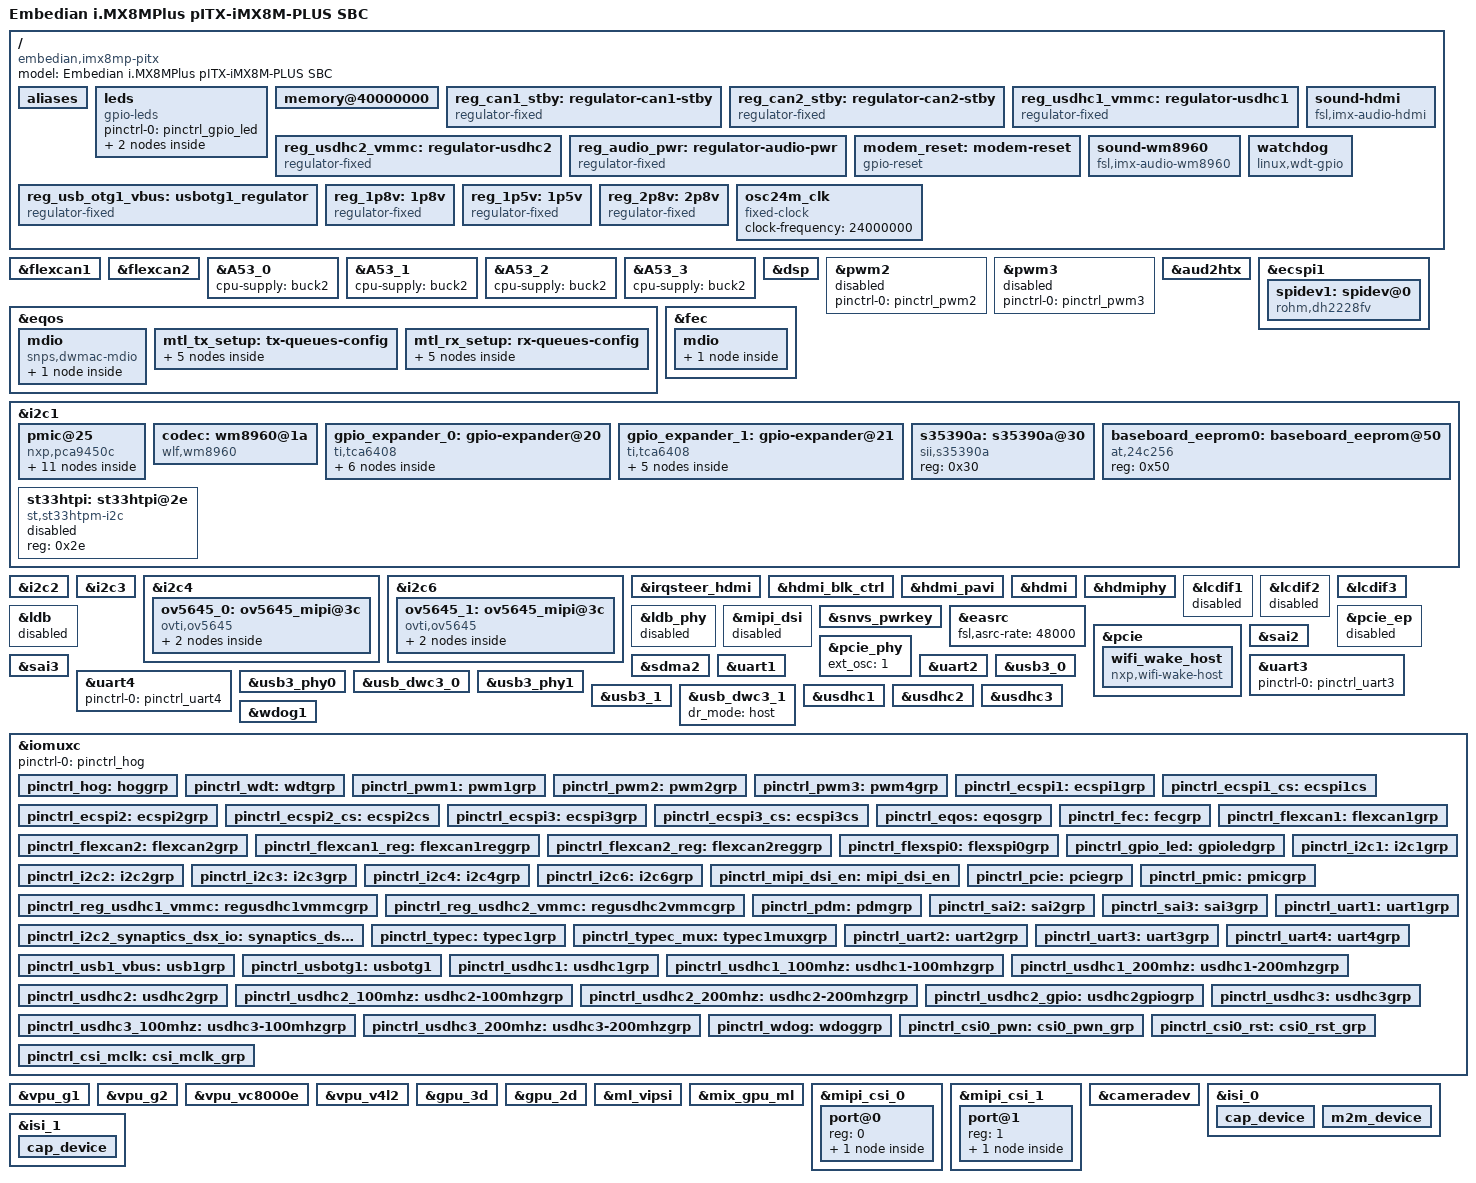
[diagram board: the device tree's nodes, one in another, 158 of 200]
// SPDX-License-Identifier: (GPL-2.0+ OR MIT)
/*
 * Copyright 2019 NXP
 * Copyright 2023 Embedian, Inc.
 */

/dts-v1/;

#include <dt-bindings/usb/pd.h>
#include "../freescale/imx8mp.dtsi"

/ {
	model = "Embedian i.MX8MPlus pITX-iMX8M-PLUS SBC";
	compatible = "embedian,imx8mp-pitx", "fsl,imx8mp";

	aliases {
		rtc0 = &s35390a;
		rtc1 = &snvs_rtc;
	};

	leds {
		compatible = "gpio-leds";
		pinctrl-names = "default";
		pinctrl-0 = <&pinctrl_gpio_led>;

		/* fault may in the event of a kernel panic, but if you want to set it manually,
		   echo 149 > /sys/class/leds/fault/brightness */

		led1 {
			label = "led1";
			gpios = <&gpio5 21 GPIO_ACTIVE_HIGH>;
			default-state = "off";
			linux,default-trigger = "heartbeat";
		};

		watchdog_enable {
			label = "watchdog_enable";
			gpios = <&gpio4 27 GPIO_ACTIVE_HIGH>;
			default-state = "on";
		};
	};

	memory@40000000 {
		device_type = "memory";
		reg = <0x0 0x40000000 0 0xc0000000>,
		      <0x1 0x00000000 0 0xc0000000>;
	};

	reg_can1_stby: regulator-can1-stby {
		compatible = "regulator-fixed";
		regulator-name = "can1-stby";
		regulator-min-microvolt = <3300000>;
		regulator-max-microvolt = <3300000>;
	};

	reg_can2_stby: regulator-can2-stby {
		compatible = "regulator-fixed";
		regulator-name = "can2-stby";
		regulator-min-microvolt = <3300000>;
		regulator-max-microvolt = <3300000>;
	};

	reg_usdhc1_vmmc: regulator-usdhc1 {
		compatible = "regulator-fixed";
		pinctrl-names = "default";
		pinctrl-0 = <&pinctrl_reg_usdhc1_vmmc>;
		regulator-name = "VSD1_3V3";
		regulator-min-microvolt = <3300000>;
		regulator-max-microvolt = <3300000>;
		gpio = <&gpio2 10 GPIO_ACTIVE_HIGH>;
		enable-active-high;
	};

	reg_usdhc2_vmmc: regulator-usdhc2 {
		compatible = "regulator-fixed";
		pinctrl-names = "default";
		pinctrl-0 = <&pinctrl_reg_usdhc2_vmmc>;
		regulator-name = "VSD2_3V3";
		regulator-min-microvolt = <3300000>;
		regulator-max-microvolt = <3300000>;
		gpio = <&gpio2 19 GPIO_ACTIVE_HIGH>;
		enable-active-high;
	};

	reg_audio_pwr: regulator-audio-pwr {
		compatible = "regulator-fixed";
		regulator-name = "aud-pwr";
		regulator-min-microvolt = <3300000>;
		regulator-max-microvolt = <3300000>;
		regulator-always-on;
	};

	modem_reset: modem-reset {
		compatible = "gpio-reset";
		reset-gpios = <&gpio_expander_1 3 GPIO_ACTIVE_LOW>;
		reset-delay-us = <2000>;
		reset-post-delay-ms = <40>;
	};

	sound-hdmi {
		compatible = "fsl,imx-audio-hdmi";
		model = "audio-hdmi";
		audio-cpu = <&aud2htx>;
		hdmi-out;
		constraint-rate = <44100>,
				<88200>,
				<176400>,
				<32000>,
				<48000>,
				<96000>,
				<192000>;
		status = "okay";
	};

	sound-wm8960 {
		compatible = "fsl,imx-audio-wm8960";
		model = "wm8960-audio";
		audio-cpu = <&sai3>;
		audio-codec = <&codec>;
		audio-asrc = <&easrc>;
		hp-det-gpio = <&gpio4 28 0>;
		audio-routing =
			"Headphone Jack", "HP_L",
			"Headphone Jack", "HP_R",
			"Ext Spk", "SPK_LP",
			"Ext Spk", "SPK_LN",
			"Ext Spk", "SPK_RP",
			"Ext Spk", "SPK_RN",
			"LINPUT1", "Mic Jack",
			"LINPUT3", "Mic Jack",
			"Mic Jack", "MICB";
	};

	watchdog: watchdog {
		compatible = "linux,wdt-gpio";
		pinctrl-names = "default";
		pinctrl-0 = <&pinctrl_wdt>;
		gpios = <&gpio4 2 GPIO_ACTIVE_LOW>;
		hw_algo = "toggle";
		hw_margin_ms = <80>;
		always-running;
	};

	reg_usb_otg1_vbus: usbotg1_regulator {
		compatible = "regulator-fixed";
		regulator-name = "usb_otg1_vbus";
		regulator-min-microvolt = <3300000>;
		regulator-max-microvolt = <3300000>;
		gpio = <&gpio1 12 GPIO_ACTIVE_HIGH>;
		enable-active-high;
		regulator-always-on;
	};

	reg_1p8v: 1p8v {
		compatible = "regulator-fixed";
		regulator-name = "1P8V";
		regulator-min-microvolt = <1800000>;
		regulator-max-microvolt = <1800000>;
		regulator-always-on;
	};

	reg_1p5v: 1p5v {
		compatible = "regulator-fixed";
		regulator-name = "1P5V";
		regulator-min-microvolt = <1500000>;
		regulator-max-microvolt = <1500000>;
		regulator-always-on;
	};

	reg_2p8v: 2p8v {
		compatible = "regulator-fixed";
		regulator-name = "2P8V";
		regulator-min-microvolt = <2800000>;
		regulator-max-microvolt = <2800000>;
		regulator-always-on;
	};

	osc24m_clk: osc24m_clk {
		compatible = "fixed-clock";
		#clock-cells = <0>;
		clock-frequency = <24000000>;
	};
};

&flexcan1 {
	pinctrl-names = "default";
	pinctrl-0 = <&pinctrl_flexcan1>;
	xceiver-supply = <&reg_can1_stby>;
	status = "okay";
};

&flexcan2 {
	pinctrl-names = "default";
	pinctrl-0 = <&pinctrl_flexcan2>;
	xceiver-supply = <&reg_can2_stby>;
	status = "okay";
};

&A53_0 {
	cpu-supply = <&buck2>;
};

&A53_1 {
	cpu-supply = <&buck2>;
};

&A53_2 {
	cpu-supply = <&buck2>;
};

&A53_3 {
	cpu-supply = <&buck2>;
};

&dsp {
	status = "okay";
};

&pwm2 {
	pinctrl-names = "default";
	pinctrl-0 = <&pinctrl_pwm2>;
	status = "disabled";
};

&pwm3 {
	pinctrl-names = "default";
	pinctrl-0 = <&pinctrl_pwm3>;
	status = "disabled";
};

&aud2htx {
	status = "okay";
};

/* SPI (on pIO) */
&ecspi1 {
	#address-cells = <1>;
	#size-cells = <0>;
	fsl,spi-num-chipselects = <1>;
	pinctrl-names = "default";
	pinctrl-0 = <&pinctrl_ecspi1 &pinctrl_ecspi1_cs>;
	cs-gpios = <&gpio5 9 GPIO_ACTIVE_LOW>;
	status = "okay";

	spidev1: spidev@0 {
		reg = <0>;
		compatible = "rohm,dh2228fv";
		spi-max-frequency = <24000000>;
	};
};

&eqos {
	pinctrl-names = "default";
	pinctrl-0 = <&pinctrl_eqos>;
	phy-mode = "rgmii-id";
	phy-handle = <&ethphy1>;
	snps,force_thresh_dma_mode;
	snps,mtl-tx-config = <&mtl_tx_setup>;
	snps,mtl-rx-config = <&mtl_rx_setup>;
	status = "okay";

	mdio {
		compatible = "snps,dwmac-mdio";
		#address-cells = <1>;
		#size-cells = <0>;

		ethphy1: ethernet-phy@1 {
			compatible = "ethernet-phy-ieee802.3-c22";
			reg = <1>;
			eee-broken-1000t;
			realtek,clkout-disable;
		};
	};

	mtl_tx_setup: tx-queues-config {
		snps,tx-queues-to-use = <5>;
		snps,tx-sched-sp;
		queue0 {
			snps,dcb-algorithm;
			snps,priority = <0x1>;
		};
		queue1 {
			snps,dcb-algorithm;
			snps,priority = <0x2>;
		};
		queue2 {
			snps,dcb-algorithm;
			snps,priority = <0x4>;
		};
		queue3 {
			snps,dcb-algorithm;
			snps,priority = <0x8>;
		};
		queue4 {
			snps,dcb-algorithm;
			snps,priority = <0xf0>;
		};
	};
	mtl_rx_setup: rx-queues-config {
		snps,rx-queues-to-use = <5>;
		snps,rx-sched-sp;
		queue0 {
			snps,dcb-algorithm;
			snps,priority = <0x1>;
			snps,map-to-dma-channel = <0>;
		};
		queue1 {
			snps,dcb-algorithm;
			snps,priority = <0x2>;
			snps,map-to-dma-channel = <1>;
		};
		queue2 {
			snps,dcb-algorithm;
			snps,priority = <0x4>;
			snps,map-to-dma-channel = <2>;
		};
		queue3 {
			snps,dcb-algorithm;
			snps,priority = <0x8>;
			snps,map-to-dma-channel = <3>;
		};
		queue4 {
			snps,dcb-algorithm;
			snps,priority = <0xf0>;
			snps,map-to-dma-channel = <4>;
		};
	};
};

&fec {
	pinctrl-names = "default";
	pinctrl-0 = <&pinctrl_fec>;
	phy-mode = "rgmii-id";
	phy-handle = <&ethphy0>;
	fsl,magic-packet;
	status = "okay";

	mdio {
		#address-cells = <1>;
		#size-cells = <0>;

		ethphy0: ethernet-phy@1 {
			compatible = "ethernet-phy-ieee802.3-c22";
			reg = <1>;
			eee-broken-1000t;
			realtek,aldps-enable;
			realtek,clkout-disable;
		};
	};
};

/* I2C1 */
&i2c1 {
	clock-frequency = <400000>;
	pinctrl-names = "default";
	pinctrl-0 = <&pinctrl_i2c1>;
	status = "okay";

	pmic@25 {
		compatible = "nxp,pca9450c";
		reg = <0x25>;
		pinctrl-names = "default";
		pinctrl-0 = <&pinctrl_pmic>;
		interrupt-parent = <&gpio1>;
		interrupts = <3 IRQ_TYPE_LEVEL_LOW>;

		regulators {
			buck1: BUCK1 {
				regulator-name = "BUCK1";
				regulator-min-microvolt = <600000>;
				regulator-max-microvolt = <2187500>;
				regulator-boot-on;
				regulator-always-on;
				regulator-ramp-delay = <3125>;
			};

			buck2: BUCK2 {
				regulator-name = "BUCK2";
				regulator-min-microvolt = <600000>;
				regulator-max-microvolt = <2187500>;
				regulator-boot-on;
				regulator-always-on;
				regulator-ramp-delay = <3125>;
				nxp,dvs-run-voltage = <950000>;
				nxp,dvs-standby-voltage = <850000>;
			};

			buck4: BUCK4{
				regulator-name = "BUCK4";
				regulator-min-microvolt = <600000>;
				regulator-max-microvolt = <3400000>;
				regulator-boot-on;
				regulator-always-on;
			};

			buck5: BUCK5{
				regulator-name = "BUCK5";
				regulator-min-microvolt = <600000>;
				regulator-max-microvolt = <3400000>;
				regulator-boot-on;
				regulator-always-on;
			};

			buck6: BUCK6 {
				regulator-name = "BUCK6";
				regulator-min-microvolt = <600000>;
				regulator-max-microvolt = <3400000>;
				regulator-boot-on;
				regulator-always-on;
			};

			ldo1: LDO1 {
				regulator-name = "LDO1";
				regulator-min-microvolt = <1600000>;
				regulator-max-microvolt = <3300000>;
				regulator-boot-on;
				regulator-always-on;
			};

			ldo2: LDO2 {
				regulator-name = "LDO2";
				regulator-min-microvolt = <800000>;
				regulator-max-microvolt = <1150000>;
				regulator-boot-on;
				regulator-always-on;
			};

			ldo3: LDO3 {
				regulator-name = "LDO3";
				regulator-min-microvolt = <800000>;
				regulator-max-microvolt = <3300000>;
				regulator-boot-on;
				regulator-always-on;
			};

			ldo4: LDO4 {
				regulator-name = "LDO4";
				regulator-min-microvolt = <800000>;
				regulator-max-microvolt = <3300000>;
				regulator-boot-on;
				regulator-always-on;
			};

			ldo5: LDO5 {
				regulator-name = "LDO5";
				regulator-min-microvolt = <1800000>;
				regulator-max-microvolt = <3300000>;
				regulator-boot-on;
				regulator-always-on;
			};
		};
	};

	codec: wm8960@1a {
		compatible = "wlf,wm8960";
		reg = <0x1a>;
		clocks = <&audio_blk_ctrl IMX8MP_CLK_AUDIO_BLK_CTRL_SAI3_MCLK1>;
		clock-names = "mclk";
		wlf,shared-lrclk;
		wlf,hp-cfg = <3 2 3>;
		wlf,gpio-cfg = <1 3>;
		SPKVDD1-supply = <&reg_audio_pwr>;
	};

	/*
	 * TCA6408 GPIO expander
	 *  0-WLAN_PWR_EN
	 *  1-M2_W_DISABLE1#
	 *  2-M2_W_DISABLE2#
	 *  3-M2_RESET#
	 *  4-PCIE_A_CKREQ#
	 *  5-PCIE_A_WAKE#
	 *  6-UART_WAKE#
	 *  7-
	*/
	gpio_expander_0: gpio-expander@20 {
		compatible = "ti,tca6408";
		reg = <0x20>;
		gpio-controller;
		vcc-supply = <&reg_1p8v>;
		#gpio-cells = <2>;
		interrupt-controller;
		#interrupt-cells = <2>;
		interrupt-parent = <&gpio4>;
		interrupts = <22 IRQ_TYPE_LEVEL_LOW>;

		wlan_pwr_en_hog {
			gpio-hog;
			gpios = <0 GPIO_ACTIVE_HIGH>;
			output-high;
			line-name = "wlan_pwr_en";
		};
		m2_w_disable1_hog {
			gpio-hog;
			gpios = <1 GPIO_ACTIVE_LOW>;
			output-low;
			line-name = "m2_w_disable1";
		};
		m2_w_disable2_hog {
			gpio-hog;
			gpios = <2 GPIO_ACTIVE_LOW>;
			output-low;
			line-name = "m2_w_disable2";
		};
		pcie_a_ckreq_hog {
			gpio-hog;
			gpios = <4 GPIO_ACTIVE_LOW>;
			input;
			line-name = "pcie_a_ckreq";
		};
		pcie_a_wake_hog {
			gpio-hog;
			gpios = <5 GPIO_ACTIVE_LOW>;
			input;
			line-name = "pcie_a_wake";
		};
		uart_wake_hog {
			gpio-hog;
			gpios = <6 GPIO_ACTIVE_LOW>;
			input;
			line-name = "uart_wake";
		};
	};

	/*
	 * TCA6408 GPIO expander
	 *  0-WWLAN_PWR_EN
	 *  1-WWAN_DISABLE1#
	 *  2-WWAN_DISABLE2#
	 *  3-WWAN_PERST#
	 *  4-NC
	 *  5-WWAN_WAKE#
	 *  6-NC
	 *  7-UIM_CD
	*/
	gpio_expander_1: gpio-expander@21 {
		compatible = "ti,tca6408";
		reg = <0x21>;
		gpio-controller;
		vcc-supply = <&reg_1p8v>;
		#gpio-cells = <2>;
		interrupt-controller;
		#interrupt-cells = <2>;
		interrupt-parent = <&gpio5>;
		interrupts = <0 IRQ_TYPE_LEVEL_LOW>;

		wwan_pwr_en_hog {
			gpio-hog;
			gpios = <0 GPIO_ACTIVE_HIGH>;
			output-high;
			line-name = "wwan_pwr_en";
		};
		wwan_w_disable1_hog {
			gpio-hog;
			gpios = <1 GPIO_ACTIVE_LOW>;
			output-low;
			line-name = "wwan_w_disable1";
		};
		wwan_w_disable2_hog {
			gpio-hog;
			gpios = <2 GPIO_ACTIVE_LOW>;
			output-low;
			line-name = "wwan_w_disable2";
		};
		wwan_wake_hog {
			gpio-hog;
			gpios = <5 GPIO_ACTIVE_LOW>;
			input;
			line-name = "wwan_wake";
		};
		uim_cd_hog {
			gpio-hog;
			gpios = <7 GPIO_ACTIVE_HIGH>;
			input;
			line-name = "uim_cd";
		};
	};

	s35390a: s35390a@30 {
		compatible = "sii,s35390a";
		reg = <0x30>;
	};

	baseboard_eeprom0: baseboard_eeprom@50 {
		compatible = "at,24c256";
		reg = <0x50>;
	};

	/* TPM */
	st33htpi: st33htpi@2e{
		compatible = "st,st33htpm-i2c";
		reg = <0x2e>;
		status = "disabled";
	};
};

/* I2C2 (LVDS) */
&i2c2 {
	clock-frequency = <100000>;
	pinctrl-names = "default";
	pinctrl-0 = <&pinctrl_i2c2>;
	status = "okay";
};

/* I2C3 (on pIO) */
&i2c3 {
	clock-frequency = <400000>;
	pinctrl-names = "default";
	pinctrl-0 = <&pinctrl_i2c3>;
	status = "okay";
};

/* I2C4 (on CAM2 and pIO) */
&i2c4 {
	clock-frequency = <400000>;
	pinctrl-names = "default";
	pinctrl-0 = <&pinctrl_i2c4>;
	status = "okay";

	ov5645_0: ov5645_mipi@3c {
		compatible = "ovti,ov5645";
		reg = <0x3c>;
		clocks = <&osc24m_clk>;
		clock-frequency = <24000000>;
		clock-names = "xclk";
		vdddo-supply = <&reg_1p8v>;
		vdda-supply = <&reg_2p8v>;
		vddd-supply = <&reg_1p5v>;
		csi_id = <1>;
		enable-gpios = <&gpio3 8 GPIO_ACTIVE_HIGH>;
		reset-gpios = <&gpio3 9 GPIO_ACTIVE_LOW>;
		mipi_csi;
                status = "okay";

                port {
                        ov5645_mipi_1_ep: endpoint {
                                remote-endpoint = <&mipi_csi1_ep>;
                                data-lanes = <1 2>;
                                clock-lanes = <0>;
                        };
                };
        };
};

/* I2C6 (on CAM1)*/
&i2c6 {
	clock-frequency = <400000>;
	pinctrl-names = "default";
	pinctrl-0 = <&pinctrl_i2c6>;
	status = "okay";

	ov5645_1: ov5645_mipi@3c {
		compatible = "ovti,ov5645";
		reg = <0x3c>;
		clocks = <&osc24m_clk>;
		clock-names = "xclk";
		clock-frequency = <24000000>;
		vdddo-supply = <&reg_1p8v>;
		vdda-supply = <&reg_2p8v>;
		vddd-supply = <&reg_1p5v>;
		csi_id = <0>;
		enable-gpios = <&gpio3 6 GPIO_ACTIVE_HIGH>;
		reset-gpios = <&gpio3 7 GPIO_ACTIVE_LOW>;
		mipi_csi;
                status = "okay";

                port {
                        ov5645_mipi_0_ep: endpoint {
                                remote-endpoint = <&mipi_csi0_ep>;
				data-lanes = <1 2>;
                                clock-lanes = <0>;
                        };
                };
        };
};

&irqsteer_hdmi {
	status = "okay";
};

&hdmi_blk_ctrl {
	status = "okay";
};

&hdmi_pavi {
	status = "okay";
};

&hdmi {
	status = "okay";
};

&hdmiphy {
	status = "okay";
};

/* MIPI-DSI */
&lcdif1 {
	status = "disabled";
};

/* LVDS */
&lcdif2 {
	status = "disabled";
};

/* HDMI */
&lcdif3 {
	status = "okay";

	thres-low  = <1 2>;		/* (FIFO * 1 / 2) */
	thres-high = <3 4>;		/* (FIFO * 3 / 4) */
};

&ldb {
	status = "disabled";
};

&ldb_phy {
	status = "disabled";
};

&mipi_dsi {
	status = "disabled";
};

&snvs_pwrkey {
	status = "okay";
};

&easrc {
	fsl,asrc-rate  = <48000>;
	status = "okay";
};

&pcie{
	pinctrl-names = "default";
	pinctrl-0 = <&pinctrl_pcie>;
	reset-gpio = <&gpio_expander_0 3 GPIO_ACTIVE_LOW>;
	ext_osc = <1>;
	clocks = <&clk IMX8MP_CLK_HSIO_ROOT>,
		 <&clk IMX8MP_CLK_PCIE_AUX>,
		 <&clk IMX8MP_CLK_HSIO_AXI>,
		 <&clk IMX8MP_CLK_PCIE_ROOT>;
	clock-names = "pcie", "pcie_aux", "pcie_phy", "pcie_bus";
	assigned-clocks = <&clk IMX8MP_CLK_HSIO_AXI>,
			  <&clk IMX8MP_CLK_PCIE_AUX>;
	assigned-clock-rates = <500000000>, <10000000>;
	assigned-clock-parents = <&clk IMX8MP_SYS_PLL2_500M>,
				 <&clk IMX8MP_SYS_PLL2_50M>;
	l1ss-disabled;
	status = "okay";

	wifi_wake_host {
		compatible = "nxp,wifi-wake-host";
		interrupt-parent = <&gpio2>;
		interrupts = <7 IRQ_TYPE_LEVEL_LOW>;
		interrupt-names = "host-wake";
	};
};

&pcie_ep{
	pinctrl-names = "default";
	pinctrl-0 = <&pinctrl_pcie>;
	ext_osc = <1>;
	clocks = <&clk IMX8MP_CLK_HSIO_ROOT>,
		 <&clk IMX8MP_CLK_PCIE_AUX>,
		 <&clk IMX8MP_CLK_HSIO_AXI>,
		 <&clk IMX8MP_CLK_PCIE_ROOT>;
	clock-names = "pcie", "pcie_aux", "pcie_phy", "pcie_bus";
	assigned-clocks = <&clk IMX8MP_CLK_HSIO_AXI>,
			  <&clk IMX8MP_CLK_PCIE_AUX>;
	assigned-clock-rates = <500000000>, <10000000>;
	assigned-clock-parents = <&clk IMX8MP_SYS_PLL2_500M>,
				 <&clk IMX8MP_SYS_PLL2_50M>;
	status = "disabled";
};

&pcie_phy{
	ext_osc = <1>;
	status = "okay";
};

/* M.2 */
&sai2 {
	#sound-dai-cells = <0>;
	pinctrl-names = "default";
	pinctrl-0 = <&pinctrl_sai2>;
	assigned-clocks = <&clk IMX8MP_CLK_SAI2>;
	assigned-clock-parents = <&clk IMX8MP_AUDIO_PLL1_OUT>;
	assigned-clock-rates = <24576000>;
	status = "okay";
};

&sai3 {
	pinctrl-names = "default";
	pinctrl-0 = <&pinctrl_sai3>;
	assigned-clocks = <&clk IMX8MP_CLK_SAI3>;
	assigned-clock-parents = <&clk IMX8MP_AUDIO_PLL1_OUT>;
	assigned-clock-rates = <24576000>;
	clocks = <&audio_blk_ctrl IMX8MP_CLK_AUDIO_BLK_CTRL_SAI3_IPG>, <&clk IMX8MP_CLK_DUMMY>,
		 <&audio_blk_ctrl IMX8MP_CLK_AUDIO_BLK_CTRL_SAI3_MCLK1>, <&clk IMX8MP_CLK_DUMMY>,
		 <&clk IMX8MP_CLK_DUMMY>;
	clock-names = "bus", "mclk0", "mclk1", "mclk2", "mclk3";
	fsl,sai-mclk-direction-output;
	status = "okay";
};

&sdma2 {
	status = "okay";
};

&uart1 { 
	/* M.2 */
	pinctrl-names = "default";
	pinctrl-0 = <&pinctrl_uart1>;
	assigned-clocks = <&clk IMX8MP_CLK_UART1>;
	assigned-clock-parents = <&clk IMX8MP_SYS_PLL1_80M>;
	fsl,uart-has-rtscts;
	status = "okay";
};

&uart2 {
	/* pIO */
	pinctrl-names = "default";
	pinctrl-0 = <&pinctrl_uart2>;
	assigned-clocks = <&clk IMX8MP_CLK_UART2>;
	assigned-clock-parents = <&clk IMX8MP_SYS_PLL1_80M>;
	fsl,uart-has-rtscts;
	status = "okay";
};

&uart3 {
	/* pIO */
	pinctrl-names = "default";
	pinctrl-0 = <&pinctrl_uart3>;
	status = "okay";
};

&uart4 {
	/* console */
	pinctrl-names = "default";
	pinctrl-0 = <&pinctrl_uart4>;
	status = "okay";
};

&usb3_phy0 {
	fsl,phy-tx-vref-tune = <0xe>;
	fsl,phy-tx-preemp-amp-tune = <3>;
	fsl,phy-tx-vboost-level = <5>;
	fsl,phy-comp-dis-tune = <7>;
	fsl,pcs-tx-deemph-3p5db = <0x21>;
	fsl,phy-pcs-tx-swing-full = <0x7f>;
	status = "okay";
};

&usb3_0 {
	pinctrl-names = "default";
	pinctrl-0 = <&pinctrl_usbotg1>;
	vbus-supply = <&reg_usb_otg1_vbus>;
	status = "okay";
};

&usb_dwc3_0 {
	dr_mode = "otg";
	hnp-disable;
	srp-disable;
	adp-disable;
	usb-role-switch;
	role-switch-default-mode = "host";
	snps,dis-u1-entry-quirk;
	snps,dis-u2-entry-quirk;
	status = "okay";
};

&usb3_phy1 {
	fsl,phy-tx-preemp-amp-tune = <3>;
	fsl,phy-tx-vref-tune = <0xb>;
	status = "okay";
};

&usb3_1 {
	status = "okay";
};

&usb_dwc3_1 {
	dr_mode = "host";
	status = "okay";
};

/* M.2 */
&usdhc1 {
	assigned-clocks = <&clk IMX8MP_CLK_USDHC1>;
	assigned-clock-rates = <400000000>;
	pinctrl-names = "default", "state_100mhz", "state_200mhz";
	pinctrl-0 = <&pinctrl_usdhc1>;
	pinctrl-1 = <&pinctrl_usdhc1_100mhz>;
	pinctrl-2 = <&pinctrl_usdhc1_200mhz>;
	vmmc-supply = <&reg_usdhc1_vmmc>;
	bus-width = <4>;
	pm-ignore-notify;
	keep-power-in-suspend;
	non-removable;
	cap-power-off-card;
	status = "okay";
};

/* SD Card */
&usdhc2 {
	assigned-clocks = <&clk IMX8MP_CLK_USDHC2>;
	assigned-clock-rates = <400000000>;
	pinctrl-names = "default", "state_100mhz", "state_200mhz";
	pinctrl-0 = <&pinctrl_usdhc2>, <&pinctrl_usdhc2_gpio>;
	pinctrl-1 = <&pinctrl_usdhc2_100mhz>, <&pinctrl_usdhc2_gpio>;
	pinctrl-2 = <&pinctrl_usdhc2_200mhz>, <&pinctrl_usdhc2_gpio>;
	cd-gpios = <&gpio2 12 GPIO_ACTIVE_LOW>;
	vmmc-supply = <&reg_usdhc2_vmmc>;
	bus-width = <4>;
	status = "okay";
};

/* eMMC */
&usdhc3 {
	assigned-clocks = <&clk IMX8MP_CLK_USDHC3>;
	assigned-clock-rates = <400000000>;
	pinctrl-names = "default", "state_100mhz", "state_200mhz";
	pinctrl-0 = <&pinctrl_usdhc3>;
	pinctrl-1 = <&pinctrl_usdhc3_100mhz>;
	pinctrl-2 = <&pinctrl_usdhc3_200mhz>;
	bus-width = <8>;
	non-removable;
	status = "okay";
};

&wdog1 {
	pinctrl-names = "default";
	pinctrl-0 = <&pinctrl_wdog>;
	fsl,ext-reset-output;
	status = "okay";
};

&iomuxc {
	pinctrl-names = "default";
	pinctrl-0 = <&pinctrl_hog>;

	pinctrl_hog: hoggrp {
		fsl,pins = <
			MX8MP_IOMUXC_HDMI_DDC_SCL__HDMIMIX_HDMI_SCL	0x400001c2
			MX8MP_IOMUXC_HDMI_DDC_SDA__HDMIMIX_HDMI_SDA	0x400001c2
			MX8MP_IOMUXC_HDMI_HPD__HDMIMIX_HDMI_HPD		0x40000010
			MX8MP_IOMUXC_HDMI_CEC__HDMIMIX_HDMI_CEC		0x40000010
			MX8MP_IOMUXC_SAI1_TXD6__GPIO4_IO18	0x19	/* LCD0_BKLT_EN */
			MX8MP_IOMUXC_SAI1_MCLK__GPIO4_IO20	0x19	/* LCD1_BKLT_EN */
			MX8MP_IOMUXC_SAI1_RXC__GPIO4_IO01	0x19	/* LCD0_VDD_EN */
			MX8MP_IOMUXC_SD2_WP__GPIO2_IO20		0x41	/* M.2_IRQ# */
			MX8MP_IOMUXC_SAI1_TXD7__GPIO4_IO19	0x141	/* TPM_IRQ# */
			MX8MP_IOMUXC_ECSPI2_MOSI__GPIO5_IO11	0x41	/* TPM_PP */
			MX8MP_IOMUXC_ECSPI2_SCLK__GPIO5_IO10	0x41	/* TPM_LP */
			MX8MP_IOMUXC_SAI2_RXC__GPIO4_IO22	0x41	/* TCA6408 IO Expander INT# (M.2) */
			MX8MP_IOMUXC_SAI3_TXC__GPIO5_IO00	0x41	/* TCA6408 IO Expander INT# (MPCIe) */
			MX8MP_IOMUXC_GPIO1_IO15__GPIO1_IO15	0x41	/* TS_INT# */
			MX8MP_IOMUXC_NAND_DQS__GPIO3_IO14	0x19	/* USB2_HUB_EN */
			MX8MP_IOMUXC_NAND_DATA00__GPIO3_IO06	0x19	/* CAM1_PWR# */
			MX8MP_IOMUXC_NAND_DATA01__GPIO3_IO07	0x19	/* CAM1_RST# */
			MX8MP_IOMUXC_SAI3_RXC__GPIO4_IO29	0x41	/* CAM1_VSYNC */
			MX8MP_IOMUXC_NAND_DATA02__GPIO3_IO08	0x19	/* CAM2_PWR# */
			MX8MP_IOMUXC_NAND_DATA03__GPIO3_IO09	0x19	/* CAM2_RST# */
			MX8MP_IOMUXC_SPDIF_EXT_CLK__GPIO5_IO05	0x19	/* EIO_PWR_EN */
			MX8MP_IOMUXC_SAI1_RXFS__GPIO4_IO00	0x41	/* CAM2_VSYNC */
		>;
	};

	pinctrl_wdt: wdtgrp {
		fsl,pins = <
			MX8MP_IOMUXC_SAI2_MCLK__GPIO4_IO27	0x19	/* WDT_EN */
			MX8MP_IOMUXC_SAI1_RXD0__GPIO4_IO02	0x19	/* WDT_T_ME_OUT# */
		>;
	};

	pinctrl_pwm1: pwm1grp {
		fsl,pins = <
			MX8MP_IOMUXC_GPIO1_IO01__PWM1_OUT	0x116
		>;
	};

	pinctrl_pwm2: pwm2grp {
		fsl,pins = <
			MX8MP_IOMUXC_SAI5_RXD0__PWM2_OUT	0x116
		>;
	};

	pinctrl_pwm3: pwm4grp {
		fsl,pins = <
			MX8MP_IOMUXC_SPDIF_TX__PWM3_OUT		0x116
		>;
	};

	pinctrl_ecspi1: ecspi1grp {
		fsl,pins = <
			MX8MP_IOMUXC_ECSPI1_SCLK__ECSPI1_SCLK	0x82
			MX8MP_IOMUXC_ECSPI1_MOSI__ECSPI1_MOSI	0x82
			MX8MP_IOMUXC_ECSPI1_MISO__ECSPI1_MISO	0x82
		>;
	};

	pinctrl_ecspi1_cs: ecspi1cs {
		fsl,pins = <
			MX8MP_IOMUXC_ECSPI1_SS0__GPIO5_IO09	0x40000
		>;
	};

	pinctrl_ecspi2: ecspi2grp {
		fsl,pins = <
			MX8MP_IOMUXC_ECSPI2_SCLK__ECSPI2_SCLK	0x82
			MX8MP_IOMUXC_ECSPI2_MOSI__ECSPI2_MOSI	0x82
			MX8MP_IOMUXC_ECSPI2_MISO__ECSPI2_MISO	0x82
		>;
	};

	pinctrl_ecspi2_cs: ecspi2cs {
		fsl,pins = <
			MX8MP_IOMUXC_ECSPI2_SS0__GPIO5_IO13	0x40000
		>;
	};

	pinctrl_ecspi3: ecspi3grp {
		fsl,pins = <
			MX8MP_IOMUXC_UART1_RXD__ECSPI3_SCLK	0x82
			MX8MP_IOMUXC_UART1_TXD__ECSPI3_MOSI	0x82
			MX8MP_IOMUXC_UART2_RXD__ECSPI3_MISO	0x82
		>;
	};

	pinctrl_ecspi3_cs: ecspi3cs {
		fsl,pins = <
			MX8MP_IOMUXC_UART2_TXD__GPIO5_IO25	0x40000
			MX8MP_IOMUXC_UART3_RXD__GPIO5_IO26	0x40000
		>;
	};

	pinctrl_eqos: eqosgrp {
		fsl,pins = <
			MX8MP_IOMUXC_ENET_MDC__ENET_QOS_MDC				0x2
			MX8MP_IOMUXC_ENET_MDIO__ENET_QOS_MDIO				0x2
			MX8MP_IOMUXC_ENET_RD0__ENET_QOS_RGMII_RD0			0x90
			MX8MP_IOMUXC_ENET_RD1__ENET_QOS_RGMII_RD1			0x90
			MX8MP_IOMUXC_ENET_RD2__ENET_QOS_RGMII_RD2			0x90
			MX8MP_IOMUXC_ENET_RD3__ENET_QOS_RGMII_RD3			0x90
			MX8MP_IOMUXC_ENET_RXC__CCM_ENET_QOS_CLOCK_GENERATE_RX_CLK	0x90
			MX8MP_IOMUXC_ENET_RX_CTL__ENET_QOS_RGMII_RX_CTL			0x90
			MX8MP_IOMUXC_ENET_TD0__ENET_QOS_RGMII_TD0			0x16
			MX8MP_IOMUXC_ENET_TD1__ENET_QOS_RGMII_TD1			0x16
			MX8MP_IOMUXC_ENET_TD2__ENET_QOS_RGMII_TD2			0x16
			MX8MP_IOMUXC_ENET_TD3__ENET_QOS_RGMII_TD3			0x16
			MX8MP_IOMUXC_ENET_TX_CTL__ENET_QOS_RGMII_TX_CTL			0x16
			MX8MP_IOMUXC_ENET_TXC__CCM_ENET_QOS_CLOCK_GENERATE_TX_CLK	0x16
			MX8MP_IOMUXC_SAI2_RXFS__GPIO4_IO21				0x42
		>;
	};

	pinctrl_fec: fecgrp {
		fsl,pins = <
			MX8MP_IOMUXC_SAI1_RXD2__ENET1_MDC		0x2
			MX8MP_IOMUXC_SAI1_RXD3__ENET1_MDIO		0x2
			MX8MP_IOMUXC_SAI1_RXD4__ENET1_RGMII_RD0		0x90
			MX8MP_IOMUXC_SAI1_RXD5__ENET1_RGMII_RD1		0x90
			MX8MP_IOMUXC_SAI1_RXD6__ENET1_RGMII_RD2		0x90
			MX8MP_IOMUXC_SAI1_RXD7__ENET1_RGMII_RD3		0x90
			MX8MP_IOMUXC_SAI1_TXC__ENET1_RGMII_RXC		0x90
			MX8MP_IOMUXC_SAI1_TXFS__ENET1_RGMII_RX_CTL	0x90
			MX8MP_IOMUXC_SAI1_TXD0__ENET1_RGMII_TD0		0x16
			MX8MP_IOMUXC_SAI1_TXD1__ENET1_RGMII_TD1		0x16
			MX8MP_IOMUXC_SAI1_TXD2__ENET1_RGMII_TD2		0x16
			MX8MP_IOMUXC_SAI1_TXD3__ENET1_RGMII_TD3		0x16
			MX8MP_IOMUXC_SAI1_TXD4__ENET1_RGMII_TX_CTL	0x16
			MX8MP_IOMUXC_SAI1_TXD5__ENET1_RGMII_TXC		0x16
			MX8MP_IOMUXC_SAI1_RXD1__GPIO4_IO03		0x42
		>;
	};

	pinctrl_flexcan1: flexcan1grp {
		fsl,pins = <
			MX8MP_IOMUXC_SAI5_RXD2__CAN1_RX		0x154
			MX8MP_IOMUXC_SAI5_RXD1__CAN1_TX		0x154
		>;
	};

	pinctrl_flexcan2: flexcan2grp {
		fsl,pins = <
			MX8MP_IOMUXC_SAI5_MCLK__CAN2_RX		0x154
			MX8MP_IOMUXC_SAI5_RXD3__CAN2_TX		0x154
		>;
	};

	pinctrl_flexcan1_reg: flexcan1reggrp {
		fsl,pins = <
			MX8MP_IOMUXC_SPDIF_EXT_CLK__GPIO5_IO05	0x154	/* CAN1_STBY */
		>;
	};

	pinctrl_flexcan2_reg: flexcan2reggrp {
		fsl,pins = <
			MX8MP_IOMUXC_SAI2_MCLK__GPIO4_IO27	0x154	/* CAN2_STBY */
		>;
	};

	pinctrl_flexspi0: flexspi0grp {
		fsl,pins = <
			MX8MP_IOMUXC_NAND_ALE__FLEXSPI_A_SCLK           0x1c2
			MX8MP_IOMUXC_NAND_CE0_B__FLEXSPI_A_SS0_B        0x82
			MX8MP_IOMUXC_NAND_DATA00__FLEXSPI_A_DATA00      0x82
			MX8MP_IOMUXC_NAND_DATA01__FLEXSPI_A_DATA01      0x82
			MX8MP_IOMUXC_NAND_DATA02__FLEXSPI_A_DATA02      0x82
			MX8MP_IOMUXC_NAND_DATA03__FLEXSPI_A_DATA03      0x82
		>;
	};

	pinctrl_gpio_led: gpioledgrp {
		fsl,pins = <
			MX8MP_IOMUXC_I2C4_SDA__GPIO5_IO21	0x19
		>;
	};

	pinctrl_i2c1: i2c1grp {
		fsl,pins = <
			MX8MP_IOMUXC_I2C1_SCL__I2C1_SCL		0x400001c2
			MX8MP_IOMUXC_I2C1_SDA__I2C1_SDA		0x400001c2
		>;
	};

	pinctrl_i2c2: i2c2grp {
		fsl,pins = <
			MX8MP_IOMUXC_I2C2_SCL__I2C2_SCL		0x400001c2
			MX8MP_IOMUXC_I2C2_SDA__I2C2_SDA		0x400001c2
		>;
	};

	pinctrl_i2c3: i2c3grp {
		fsl,pins = <
			MX8MP_IOMUXC_I2C3_SCL__I2C3_SCL		0x400001c2
			MX8MP_IOMUXC_I2C3_SDA__I2C3_SDA		0x400001c2
		>;
	};

	pinctrl_i2c4: i2c4grp {
		fsl,pins = <
			MX8MP_IOMUXC_ECSPI2_MISO__I2C4_SCL	0x400001c3
			MX8MP_IOMUXC_ECSPI2_SS0__I2C4_SDA	0x400001c3
		>;
	};

	pinctrl_i2c6: i2c6grp {
		fsl,pins = <
			MX8MP_IOMUXC_SAI5_RXFS__I2C6_SCL	0x400001c3
			MX8MP_IOMUXC_SAI5_RXC__I2C6_SDA		0x400001c3
		>;
	};

	pinctrl_mipi_dsi_en: mipi_dsi_en {
		fsl,pins = <
			MX8MP_IOMUXC_GPIO1_IO08__GPIO1_IO08	0x16
		>;
	};

	pinctrl_pcie: pciegrp {
		fsl,pins = <
			MX8MP_IOMUXC_I2C4_SCL__PCIE_CLKREQ_B		0x60 /* open drain, pull up */
		>;
	};

	pinctrl_pmic: pmicgrp {
		fsl,pins = <
			MX8MP_IOMUXC_GPIO1_IO03__GPIO1_IO03	0x000001c0
		>;
	};

	pinctrl_reg_usdhc1_vmmc: regusdhc1vmmcgrp {
		fsl,pins = <
			MX8MP_IOMUXC_SD1_RESET_B__GPIO2_IO10    0x41
		>;
	};

	pinctrl_reg_usdhc2_vmmc: regusdhc2vmmcgrp {
		fsl,pins = <
			MX8MP_IOMUXC_SD2_RESET_B__GPIO2_IO19	0x40
		>;
	};

	pinctrl_pdm: pdmgrp {
		fsl,pins = <
			MX8MP_IOMUXC_SAI5_RXC__AUDIOMIX_PDM_CLK		0xd6
			MX8MP_IOMUXC_SAI5_RXD0__AUDIOMIX_PDM_BIT_STREAM00	0xd6
			MX8MP_IOMUXC_SAI5_RXD1__AUDIOMIX_PDM_BIT_STREAM01	0xd6
			MX8MP_IOMUXC_SAI5_RXD2__AUDIOMIX_PDM_BIT_STREAM02	0xd6
			MX8MP_IOMUXC_SAI5_RXD3__AUDIOMIX_PDM_BIT_STREAM03	0xd6
		>;
	};

	pinctrl_sai2: sai2grp {
		fsl,pins = <
			MX8MP_IOMUXC_SAI2_TXC__AUDIOMIX_SAI2_TX_BCLK	0xd6
			MX8MP_IOMUXC_SAI2_TXFS__AUDIOMIX_SAI2_TX_SYNC	0xd6
			MX8MP_IOMUXC_SAI2_TXD0__AUDIOMIX_SAI2_TX_DATA00	0xd6
			MX8MP_IOMUXC_SAI2_RXD0__AUDIOMIX_SAI2_RX_DATA00	0xd6
		>;
	};

	pinctrl_sai3: sai3grp {
		fsl,pins = <
			MX8MP_IOMUXC_SAI3_TXFS__AUDIOMIX_SAI3_TX_SYNC		0xd6
			MX8MP_IOMUXC_NAND_ALE__AUDIOMIX_SAI3_TX_BCLK		0xd6
			MX8MP_IOMUXC_SAI3_RXD__AUDIOMIX_SAI3_RX_DATA00		0xd6
			MX8MP_IOMUXC_NAND_CE0_B__AUDIOMIX_SAI3_TX_DATA00	0xd6
			MX8MP_IOMUXC_SAI3_MCLK__AUDIOMIX_SAI3_MCLK		0xd6
			MX8MP_IOMUXC_SAI3_RXFS__GPIO4_IO28			0x41
		>;
	};

	pinctrl_i2c2_synaptics_dsx_io: synaptics_dsx_iogrp {
		fsl,pins = <
			MX8MP_IOMUXC_GPIO1_IO09__GPIO1_IO09		0x16
		>;
	};

	pinctrl_uart1: uart1grp {
		fsl,pins = <
			MX8MP_IOMUXC_UART1_RXD__UART1_DCE_RX	0x140
			MX8MP_IOMUXC_UART1_TXD__UART1_DCE_TX	0x140
			MX8MP_IOMUXC_UART3_RXD__UART1_DCE_CTS	0x140
			MX8MP_IOMUXC_UART3_TXD__UART1_DCE_RTS	0x140
		>;
	};

	pinctrl_typec: typec1grp {
		fsl,pins = <
			MX8MP_IOMUXC_SAI1_TXD7__GPIO4_IO19	0x1c4
		>;
	};

	pinctrl_typec_mux: typec1muxgrp {
		fsl,pins = <
			MX8MP_IOMUXC_SAI1_MCLK__GPIO4_IO20	0x16
		>;
	};

	pinctrl_uart2: uart2grp {
		fsl,pins = <
			MX8MP_IOMUXC_UART2_RXD__UART2_DCE_RX	0x140
			MX8MP_IOMUXC_UART2_TXD__UART2_DCE_TX	0x140
			MX8MP_IOMUXC_SD1_DATA4__UART2_DCE_RTS	0x140
			MX8MP_IOMUXC_SD1_DATA5__UART2_DCE_CTS	0x140
		>;
	};

	pinctrl_uart3: uart3grp {
		fsl,pins = <
			MX8MP_IOMUXC_SD1_DATA7__UART3_DCE_RX	0x49
			MX8MP_IOMUXC_SD1_DATA6__UART3_DCE_TX	0x49
		>;
	};

	pinctrl_uart4: uart4grp {
		fsl,pins = <
			MX8MP_IOMUXC_UART4_RXD__UART4_DCE_RX	0x140
			MX8MP_IOMUXC_UART4_TXD__UART4_DCE_TX	0x140
		>;
	};

	pinctrl_usb1_vbus: usb1grp {
		fsl,pins = <
			MX8MP_IOMUXC_GPIO1_IO14__USB2_PWR	0x10
		>;
	};

	pinctrl_usbotg1: usbotg1 {
		fsl,pins = <
			MX8MP_IOMUXC_GPIO1_IO10__USB1_ID	0x41	/* USB1_ID */
			MX8MP_IOMUXC_GPIO1_IO12__GPIO1_IO12	0x19	/* USB1_EN */
			MX8MP_IOMUXC_GPIO1_IO13__GPIO1_IO13	0x41	/* USB1_OC# */
		>;
	};

	pinctrl_usdhc1: usdhc1grp {
		fsl,pins = <
			MX8MP_IOMUXC_SD1_CLK__USDHC1_CLK	0x190
			MX8MP_IOMUXC_SD1_CMD__USDHC1_CMD	0x1d0
			MX8MP_IOMUXC_SD1_DATA0__USDHC1_DATA0	0x1d0
			MX8MP_IOMUXC_SD1_DATA1__USDHC1_DATA1	0x1d0
			MX8MP_IOMUXC_SD1_DATA2__USDHC1_DATA2	0x1d0
			MX8MP_IOMUXC_SD1_DATA3__USDHC1_DATA3	0x1d0
			MX8MP_IOMUXC_SD1_STROBE__USDHC1_STROBE	0x190
		>;
	};

	pinctrl_usdhc1_100mhz: usdhc1-100mhzgrp {
		fsl,pins = <
			MX8MP_IOMUXC_SD1_CLK__USDHC1_CLK	0x194
			MX8MP_IOMUXC_SD1_CMD__USDHC1_CMD	0x1d4
			MX8MP_IOMUXC_SD1_DATA0__USDHC1_DATA0	0x1d4
			MX8MP_IOMUXC_SD1_DATA1__USDHC1_DATA1	0x1d4
			MX8MP_IOMUXC_SD1_DATA2__USDHC1_DATA2	0x1d4
			MX8MP_IOMUXC_SD1_DATA3__USDHC1_DATA3	0x1d4
			MX8MP_IOMUXC_SD1_STROBE__USDHC1_STROBE	0x194
		>;
	};

	pinctrl_usdhc1_200mhz: usdhc1-200mhzgrp {
		fsl,pins = <
			MX8MP_IOMUXC_SD1_CLK__USDHC1_CLK	0x196
			MX8MP_IOMUXC_SD1_CMD__USDHC1_CMD	0x1d6
			MX8MP_IOMUXC_SD1_DATA0__USDHC1_DATA0	0x1d6
			MX8MP_IOMUXC_SD1_DATA1__USDHC1_DATA1	0x1d6
			MX8MP_IOMUXC_SD1_DATA2__USDHC1_DATA2	0x1d6
			MX8MP_IOMUXC_SD1_DATA3__USDHC1_DATA3	0x1d6
			MX8MP_IOMUXC_SD1_STROBE__USDHC1_STROBE	0x196
		>;
	};

	pinctrl_usdhc2: usdhc2grp {
		fsl,pins = <
			MX8MP_IOMUXC_SD2_CLK__USDHC2_CLK	0x190
			MX8MP_IOMUXC_SD2_CMD__USDHC2_CMD	0x1d0
			MX8MP_IOMUXC_SD2_DATA0__USDHC2_DATA0	0x1d0
			MX8MP_IOMUXC_SD2_DATA1__USDHC2_DATA1	0x1d0
			MX8MP_IOMUXC_SD2_DATA2__USDHC2_DATA2	0x1d0
			MX8MP_IOMUXC_SD2_DATA3__USDHC2_DATA3	0x1d0
			MX8MP_IOMUXC_GPIO1_IO04__USDHC2_VSELECT	0xc0
		>;
	};

	pinctrl_usdhc2_100mhz: usdhc2-100mhzgrp {
		fsl,pins = <
			MX8MP_IOMUXC_SD2_CLK__USDHC2_CLK	0x194
			MX8MP_IOMUXC_SD2_CMD__USDHC2_CMD	0x1d4
			MX8MP_IOMUXC_SD2_DATA0__USDHC2_DATA0	0x1d4
			MX8MP_IOMUXC_SD2_DATA1__USDHC2_DATA1	0x1d4
			MX8MP_IOMUXC_SD2_DATA2__USDHC2_DATA2	0x1d4
			MX8MP_IOMUXC_SD2_DATA3__USDHC2_DATA3	0x1d4
			MX8MP_IOMUXC_GPIO1_IO04__USDHC2_VSELECT 0xc0
		>;
	};

	pinctrl_usdhc2_200mhz: usdhc2-200mhzgrp {
		fsl,pins = <
			MX8MP_IOMUXC_SD2_CLK__USDHC2_CLK	0x196
			MX8MP_IOMUXC_SD2_CMD__USDHC2_CMD	0x1d6
			MX8MP_IOMUXC_SD2_DATA0__USDHC2_DATA0	0x1d6
			MX8MP_IOMUXC_SD2_DATA1__USDHC2_DATA1	0x1d6
			MX8MP_IOMUXC_SD2_DATA2__USDHC2_DATA2	0x1d6
			MX8MP_IOMUXC_SD2_DATA3__USDHC2_DATA3	0x1d6
			MX8MP_IOMUXC_GPIO1_IO04__USDHC2_VSELECT 0xc0
		>;
	};

	pinctrl_usdhc2_gpio: usdhc2gpiogrp {
		fsl,pins = <
			MX8MP_IOMUXC_SD2_CD_B__GPIO2_IO12	0x1c4
		>;
	};

	pinctrl_usdhc3: usdhc3grp {
		fsl,pins = <
			MX8MP_IOMUXC_NAND_WE_B__USDHC3_CLK	0x190
			MX8MP_IOMUXC_NAND_WP_B__USDHC3_CMD	0x1d0
			MX8MP_IOMUXC_NAND_DATA04__USDHC3_DATA0	0x1d0
			MX8MP_IOMUXC_NAND_DATA05__USDHC3_DATA1	0x1d0
			MX8MP_IOMUXC_NAND_DATA06__USDHC3_DATA2	0x1d0
			MX8MP_IOMUXC_NAND_DATA07__USDHC3_DATA3	0x1d0
			MX8MP_IOMUXC_NAND_RE_B__USDHC3_DATA4	0x1d0
			MX8MP_IOMUXC_NAND_CE2_B__USDHC3_DATA5	0x1d0
			MX8MP_IOMUXC_NAND_CE3_B__USDHC3_DATA6	0x1d0
			MX8MP_IOMUXC_NAND_CLE__USDHC3_DATA7	0x1d0
			MX8MP_IOMUXC_NAND_CE1_B__USDHC3_STROBE	0x190
		>;
	};

	pinctrl_usdhc3_100mhz: usdhc3-100mhzgrp {
		fsl,pins = <
			MX8MP_IOMUXC_NAND_WE_B__USDHC3_CLK	0x194
			MX8MP_IOMUXC_NAND_WP_B__USDHC3_CMD	0x1d4
			MX8MP_IOMUXC_NAND_DATA04__USDHC3_DATA0	0x1d4
			MX8MP_IOMUXC_NAND_DATA05__USDHC3_DATA1	0x1d4
			MX8MP_IOMUXC_NAND_DATA06__USDHC3_DATA2	0x1d4
			MX8MP_IOMUXC_NAND_DATA07__USDHC3_DATA3	0x1d4
			MX8MP_IOMUXC_NAND_RE_B__USDHC3_DATA4	0x1d4
			MX8MP_IOMUXC_NAND_CE2_B__USDHC3_DATA5	0x1d4
			MX8MP_IOMUXC_NAND_CE3_B__USDHC3_DATA6	0x1d4
			MX8MP_IOMUXC_NAND_CLE__USDHC3_DATA7	0x1d4
			MX8MP_IOMUXC_NAND_CE1_B__USDHC3_STROBE	0x194
		>;
	};

	pinctrl_usdhc3_200mhz: usdhc3-200mhzgrp {
		fsl,pins = <
			MX8MP_IOMUXC_NAND_WE_B__USDHC3_CLK	0x196
			MX8MP_IOMUXC_NAND_WP_B__USDHC3_CMD	0x1d6
			MX8MP_IOMUXC_NAND_DATA04__USDHC3_DATA0	0x1d6
			MX8MP_IOMUXC_NAND_DATA05__USDHC3_DATA1	0x1d6
			MX8MP_IOMUXC_NAND_DATA06__USDHC3_DATA2	0x1d6
			MX8MP_IOMUXC_NAND_DATA07__USDHC3_DATA3	0x1d6
			MX8MP_IOMUXC_NAND_RE_B__USDHC3_DATA4	0x1d6
			MX8MP_IOMUXC_NAND_CE2_B__USDHC3_DATA5	0x1d6
			MX8MP_IOMUXC_NAND_CE3_B__USDHC3_DATA6	0x1d6
			MX8MP_IOMUXC_NAND_CLE__USDHC3_DATA7	0x1d6
			MX8MP_IOMUXC_NAND_CE1_B__USDHC3_STROBE	0x196
		>;
	};

	pinctrl_wdog: wdoggrp {
		fsl,pins = <
			MX8MP_IOMUXC_GPIO1_IO02__WDOG1_WDOG_B	0x166
		>;
	};

	pinctrl_csi0_pwn: csi0_pwn_grp {
		fsl,pins = <
			MX8MP_IOMUXC_NAND_DATA00__GPIO3_IO06	0x10
		>;
	};

	pinctrl_csi0_rst: csi0_rst_grp {
		fsl,pins = <
			MX8MP_IOMUXC_NAND_DATA01__GPIO3_IO07	0x10
		>;
	};

	pinctrl_csi_mclk: csi_mclk_grp {
		fsl,pins = <
			MX8MP_IOMUXC_GPIO1_IO14__CCM_CLKO1	0x50
		>;
	};
};

&vpu_g1 {
	status = "okay";
};

&vpu_g2 {
	status = "okay";
};

&vpu_vc8000e {
	status = "okay";
};

&vpu_v4l2 {
	status = "okay";
};

&gpu_3d {
	status = "okay";
};

&gpu_2d {
	status = "okay";
};

&ml_vipsi {
	status = "okay";
};

&mix_gpu_ml {
	status = "okay";
};

&mipi_csi_0 {
	#address-cells = <1>;
	#size-cells = <0>;
	status = "okay";

	port@0 {
		reg = <0>;
		mipi_csi0_ep: endpoint {
			remote-endpoint = <&ov5645_mipi_0_ep>;
			data-lanes = <2>;
			csis-hs-settle = <13>;
			csis-clk-settle = <2>;
			csis-wclk;
		};
	};
};

&mipi_csi_1 {
	#address-cells = <1>;
	#size-cells = <0>;
	status = "okay";

	/* Camera 1  MIPI CSI-2 (CSIS1) */
	port@1 {
		reg = <1>;
		mipi_csi1_ep: endpoint {
			remote-endpoint = <&ov5645_mipi_1_ep>;
			data-lanes = <2>;
			csis-hs-settle = <13>;
			csis-clk-settle = <2>;
			csis-wclk;
		};
	};
};

&cameradev {
	status = "okay";
};

&isi_0 {
	status = "okay";

	cap_device {
		status = "okay";
	};

	m2m_device {
		status = "okay";
	};
};

&isi_1 {
	status = "okay";

	cap_device {
		status = "okay";
	};
};
